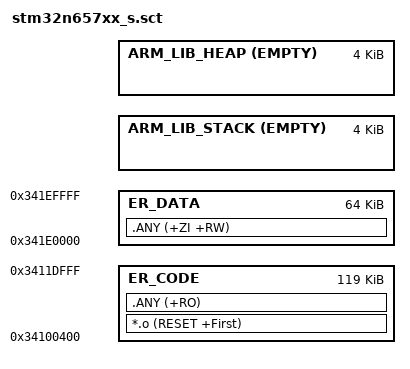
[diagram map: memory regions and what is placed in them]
#! armclang --target=arm-arm-none-eabi -march=armv8-m.main -E -xc

/*
 * Copyright (c) 2017-2018 ARM Limited
 *
 * Licensed under the Apache License, Version 2.0 (the "License");
 * you may not use this file except in compliance with the License.
 * You may obtain a copy of the License at
 *
 *     http://www.apache.org/licenses/LICENSE-2.0
 *
 * Unless required by applicable law or agreed to in writing, software
 * distributed under the License is distributed on an "AS IS" BASIS,
 * WITHOUT WARRANTIES OR CONDITIONS OF ANY KIND, either express or implied.
 * See the License for the specific language governing permissions and
 * limitations under the License.
 */

#define CODE_S_ADDRESS 0x34100400        /* This define is updated automatically from OEMuROT_Boot project */
#define CODE_S_SIZE 0x20000              /* This define is updated automatically from OEMuROT_Boot project */
#define DATA_S_ADDRESS 0x341e0000        /* This define is updated automatically from OEMuROT_Boot project */
#define DATA_S_SIZE 0x10000              /* This define is updated automatically from OEMuROT_Boot project */

#define IMAGE_HEADER_SIZE 0x400  /* mcuboot header size */
#define TRAILER_MAX_SIZE 0x2000  /* mcuboot trailer max size */

#define __STACK_SIZE    0x00001000
#define __HEAP_SIZE     0x00001000

LR_CODE CODE_S_ADDRESS {
    ER_CODE CODE_S_ADDRESS CODE_S_SIZE-IMAGE_HEADER_SIZE-TRAILER_MAX_SIZE {
        *.o (RESET +First)
        .ANY (+RO)
    }

    ER_DATA DATA_S_ADDRESS DATA_S_SIZE {
        .ANY (+ZI +RW)
    }

    /* MSP */
    ARM_LIB_STACK +0 ALIGN 32 EMPTY __STACK_SIZE {
    }

    ARM_LIB_HEAP +0 ALIGN 8 EMPTY __HEAP_SIZE {
    }
}
